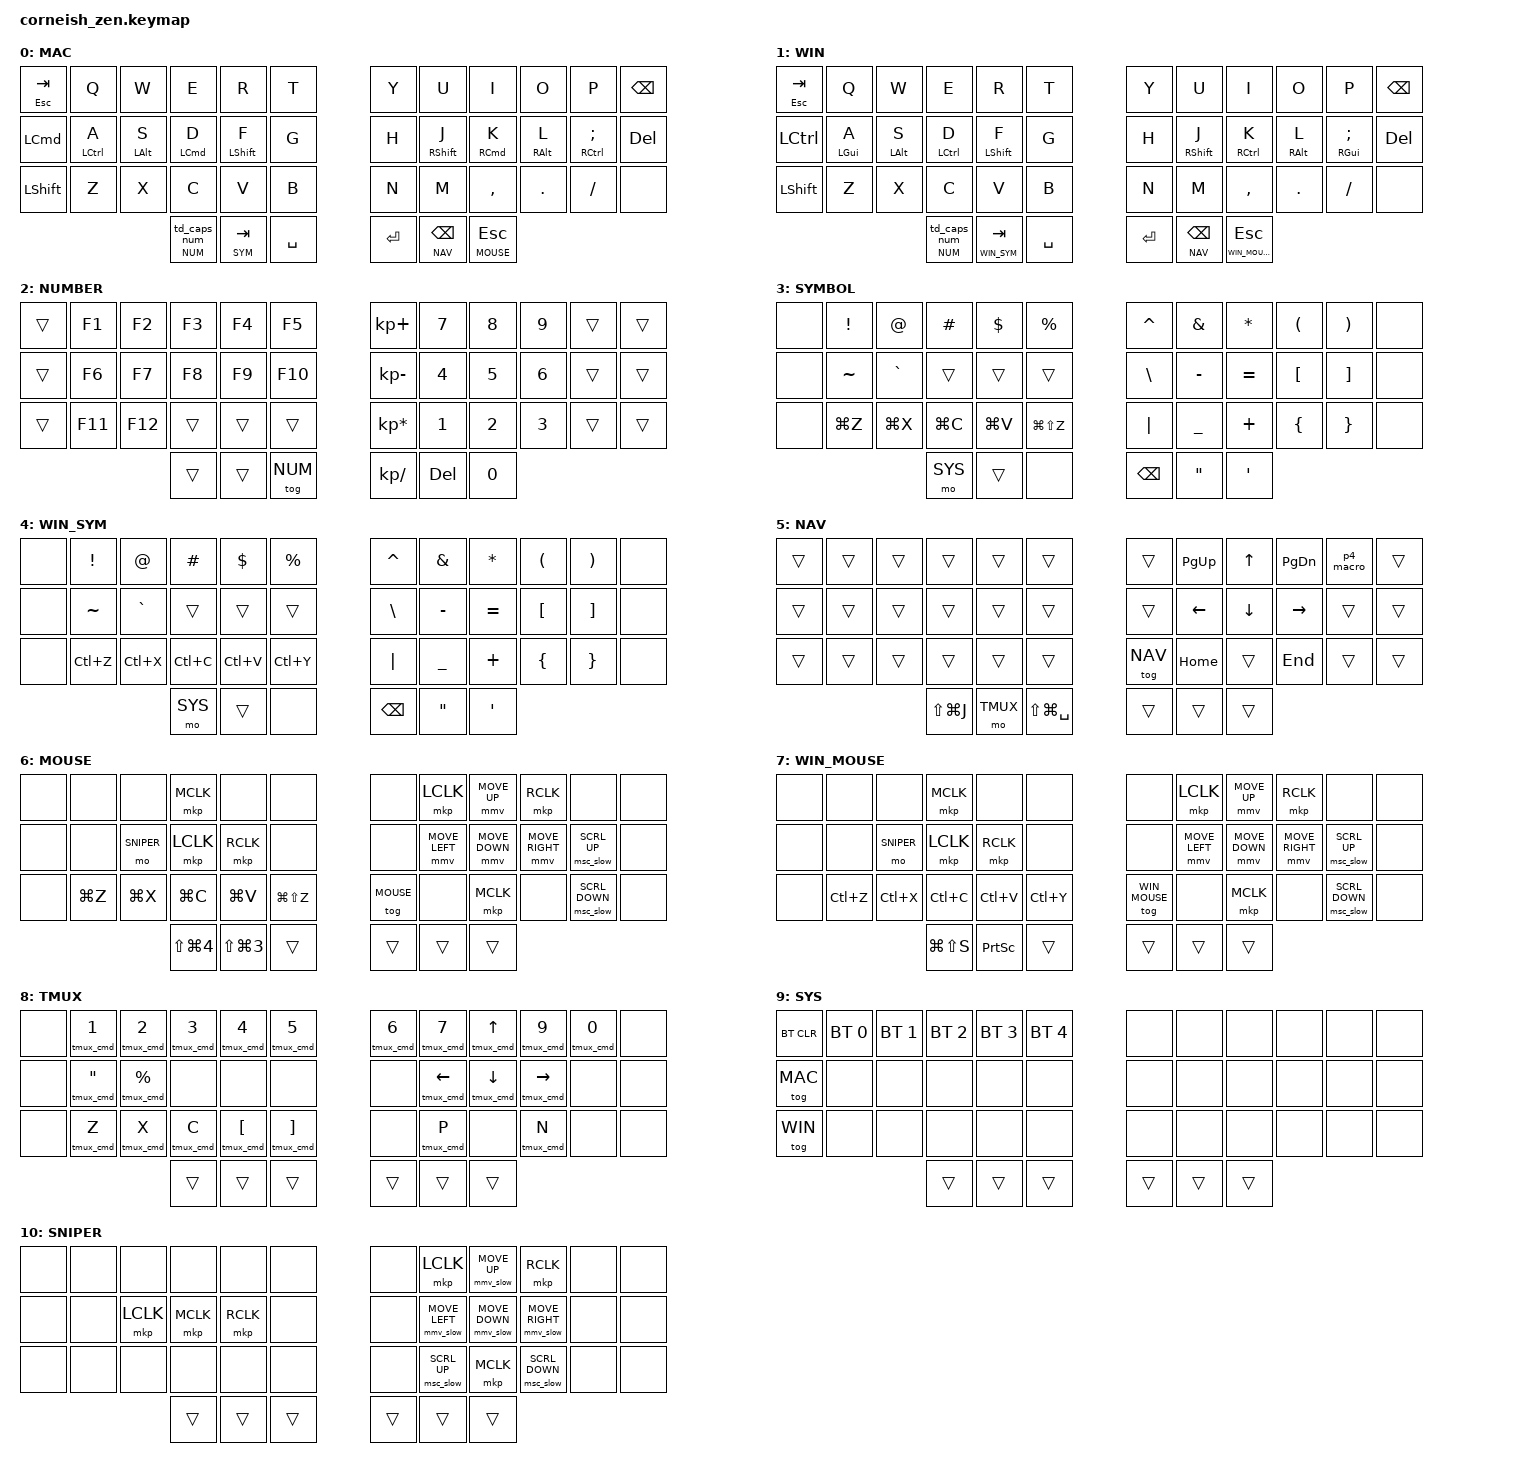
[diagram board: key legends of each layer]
#include <behaviors.dtsi>
#include <dt-bindings/zmk/keys.h>
#include <dt-bindings/zmk/bt.h>
#include <dt-bindings/zmk/pointing.h>

// 定義層級名稱（Layer Names）
#define MAC       0
#define WIN       1
#define NUM       2
#define SYM       3
#define WIN_SYM   4
#define NAV       5
#define MOUSE     6
#define WIN_MOUSE 7
#define TMUX      8
#define SYS       9
#define SNIPER   10
/* 頂部定義 Corne 鍵位索引別名 */
#define K_Q  1
#define K_W  2
#define K_E  3
#define K_R  4
#define K_T  5
#define K_Y  6
#define K_U  7
#define K_I  8
#define K_O  9
#define K_P 10

#define K_A 13
#define K_S 14
#define K_D 15
#define K_F 16
#define K_G 17
#define K_H 18
#define K_J 19
#define K_K 20
#define K_L 21
#define K_SEMI 22

#define K_Z 25
#define K_X 26
#define K_C 27
#define K_V 28
#define K_B 29
#define K_N 30
#define K_M 31
#define K_COMMA 32
#define K_DOT 33
#define K_SLASH 34

// 定義成對括號產生器模板
#define ZMK_PAIR_MACRO(name, left_key, right_key) \
    name: name { \
        compatible = "zmk,behavior-macro"; \
        #binding-cells = <0>; \
        wait-ms = <10>; \
        tap-ms = <10>; \
        bindings = <&kp left_key &kp right_key &kp LEFT>; \
    };

/* 基礎 2 鍵 Combo 模板 (預設只在 MAC 與 WIN 基礎層生效) */
#define ZMK_COMBO_2(NAME, BINDING, KEY1, KEY2) \
    combo_##NAME { \
        timeout-ms = <35>; \
        require-prior-idle-ms = <150>; \
        bindings = <BINDING>; \
        key-positions = <KEY1 KEY2>; \
        layers = <MAC WIN>; \
    };

/* 垂直捏合專用模板 (超短 timeout，單指觸發零誤觸) */
#define ZMK_VERTICAL_COMBO(NAME, BINDING, TOP_KEY, BOTTOM_KEY) \
    combo_vert_##NAME { \
        timeout-ms = <25>; \
        require-prior-idle-ms = <120>; \
        bindings = <BINDING>; \
        key-positions = <TOP_KEY BOTTOM_KEY>; \
        layers = <MAC WIN>; \
    };

/* 3 鍵爪形 Combo 模板 (系統級危險操作) */
#define ZMK_COMBO_3(NAME, BINDING, KEY1, KEY2, KEY3) \
    combo_##NAME { \
        timeout-ms = <50>; \
        bindings = <BINDING>; \
        key-positions = <KEY1 KEY2 KEY3>; \
        layers = <MAC WIN>; \
    };

/ {
    chosen {
        zmk,matrix_transform = &default_transform;
        // zmk,matrix_transform = &five_column_transform;
    };



    macros {
        tmux_cmd: tmux_cmd {
            compatible = "zmk,behavior-macro-one-param";
            #binding-cells = <1>;
            wait-ms = <10>;
            tap-ms = <10>;
            bindings
                = <&macro_press &kp LCTRL>
                , <&macro_tap &kp B>
                , <&macro_release &kp LCTRL>
                , <&macro_param_1to1>
                , <&macro_tap &kp MACRO_PLACEHOLDER>;
        };
        ZMK_PAIR_MACRO(pair_parens,   LPAR, RPAR)
        ZMK_PAIR_MACRO(pair_brackets, LBKT, RBKT)
        ZMK_PAIR_MACRO(pair_braces,   LBRC, RBRC)
        ZMK_PAIR_MACRO(pair_angles,   LT,   GT)
        ZMK_PAIR_MACRO(pair_dquotes,   DQT,  DQT)
        ZMK_PAIR_MACRO(pair_squotes,   SQT,  SQT)
        p4_macro: p4_macro {
            compatible = "zmk,behavior-macro";
            #binding-cells = <0>;
            wait-ms = <10>;
            tap-ms = <10>;
            bindings
                = <&kp P>
                , <&kp N4>;
        };
    };
    
    behaviors {
        hml: home_row_mod_left {
            compatible = "zmk,behavior-hold-tap";
            #binding-cells = <2>;
            flavor = "balanced";
            require-prior-idle-ms = <150>;
            tapping-term-ms = <280>;
            quick-tap-ms = <175>;
            bindings = <&kp>, <&kp>;
            hold-trigger-key-positions = <6 7 8 9 10 11 18 19 20 21 22 23 30 31 32 33 34 35 39 40 41>; // 右半部所有鍵位索引
            hold-trigger-on-release;
        };

        hmr: home_row_mod_right {
            compatible = "zmk,behavior-hold-tap";
            #binding-cells = <2>;
            flavor = "balanced";
            require-prior-idle-ms = <150>;
            tapping-term-ms = <280>;
            quick-tap-ms = <175>;
            bindings = <&kp>, <&kp>;
            hold-trigger-key-positions = <0 1 2 3 4 5 12 13 14 15 16 17 24 25 26 27 28 29 36 37 38>; // 左半部所有鍵位索引
            hold-trigger-on-release;
        };

        smart_caps: smart_caps {
            compatible = "zmk,behavior-caps-word";
            #binding-cells = <0>;
            continue-list = <UNDERSCORE MINUS BSPC DELETE>;
        };

        // 精準慢速移動游標（Sniper Move）
        mmv_slow: mmv_slow {
            compatible = "zmk,behavior-input-two-axis";
            #binding-cells = <1>;
            x-input-code = <INPUT_REL_X>;
            y-input-code = <INPUT_REL_Y>;
            time-to-max-speed-ms = <0>;
            acceleration-exponent = <0>;
        };

        // 精準慢速滾輪（Sniper Scroll）
        msc_slow: msc_slow {
            compatible = "zmk,behavior-input-two-axis";
            #binding-cells = <1>;
            x-input-code = <INPUT_REL_HWHEEL>;
            y-input-code = <INPUT_REL_WHEEL>;
            time-to-max-speed-ms = <0>;
            acceleration-exponent = <0>;
        };
        // num word
        // 1. 定義 Tap Dance：單擊輸出 CAPS，雙擊切換/鎖定 NUM 層
        td_caps_num: td_caps_num {
            compatible = "zmk,behavior-tap-dance";
            #binding-cells = <0>;
            tapping-term-ms = <200>;
            bindings = <&kp CAPS>, <&tog NUM>;
        };

        // 2. 定義複合 Hold-Tap：長按暫時切到 NUM 層，點擊交由 Tap Dance 處理
        lt_num_td: lt_num_td {
            compatible = "zmk,behavior-hold-tap";
            #binding-cells = <2>;
            flavor = "tap-preferred";
            tapping-term-ms = <200>;
            quick-tap-ms = <150>;
            bindings = <&mo>, <&td_caps_num>;
        };
    };

    combos {
        compatible = "zmk,combos";
        /* --- 系統控制 --- */
        
        ZMK_COMBO_2(caps_word,  &smart_caps,        K_Z, K_X)
        

        /* --- 垂直捏合：成對括號巨集 --- */
        ZMK_VERTICAL_COMBO(esc,        &kp ESC,            K_Q, K_A)
        ZMK_VERTICAL_COMBO(homerow,    &kp LS(LG(SPACE)),  K_F, K_V)
        
        ZMK_VERTICAL_COMBO(del,        &kp DEL,            K_T, K_G)
        ZMK_VERTICAL_COMBO(bspc,       &kp BSPC,           K_Y, K_H)
        ZMK_VERTICAL_COMBO(bspc2,       &kp BSPC,           K_SEMI, K_SLASH)

        ZMK_VERTICAL_COMBO(parens,   &pair_parens,   K_I, K_K)
        ZMK_VERTICAL_COMBO(brackets, &pair_brackets, K_O, K_L)
        ZMK_VERTICAL_COMBO(braces,   &pair_braces,   K_K, K_COMMA)
        ZMK_VERTICAL_COMBO(angles,   &pair_angles,   K_L, K_DOT)
        ZMK_VERTICAL_COMBO(squote,   &pair_squotes,   K_P, K_SEMI)
        

        ZMK_VERTICAL_COMBO(minus,   &kp MINUS,   K_U, K_J)
        /* --- 符號快捷 --- */
        ZMK_VERTICAL_COMBO(underscore,   &kp UNDER,   K_J, K_M)
        ZMK_VERTICAL_COMBO(dquote,   &pair_dquotes,   K_H, K_N)

        /* --- 3 鍵系統危險操作 --- */
        ZMK_COMBO_3(lock_screen, &kp LG(LC(Q)),     K_Q, K_W, K_E)
      
    };
};

/ {
    keymap {
        compatible = "zmk,keymap";

        // Layer 0: Mac 預設層
        default_layer {
            display-name = "MAC";
            bindings = <
    &mt ESC TAB     &kp Q        &kp W        &kp E        &kp R        &kp T     &kp Y   &kp U        &kp I        &kp O        &kp P           &kp BACKSPACE    
    &kp LCMD        &hml LCTRL A &hml LALT S  &hml LCMD D  &hml LSHFT F &kp G     &kp H   &hmr RSHFT J &hmr RCMD K  &hmr RALT L  &hmr RCTRL SEMI &kp DEL    
    &kp LSHFT       &kp Z        &kp X        &kp C        &kp V        &kp B     &kp N   &kp M        &kp COMMA    &kp DOT      &kp FSLH        &none  
                                        &lt_num_td NUM 0 &lt SYM TAB  &kp SPACE    &kp RET &lt NAV BACKSPACE         &lt MOUSE ESC   
            >;
        };

        // Layer 1: Windows 預設層
        win_layer {
            display-name = "WIN";
            bindings = <
    &mt ESC TAB   &kp Q        &kp W        &kp E        &kp R        &kp T     &kp Y   &kp U        &kp I        &kp O        &kp P           &kp BACKSPACE  
    &kp LCTRL     &hml LGUI A  &hml LALT S  &hml LCTRL D &hml LSHFT F &kp G     &kp H   &hmr RSHFT J &hmr RCTRL K &hmr RALT L  &hmr RGUI SEMI  &kp DEL    
    &kp LSHFT     &kp Z        &kp X        &kp C        &kp V        &kp B     &kp N   &kp M        &kp COMMA    &kp DOT      &kp FSLH        &none    
                                        &lt_num_td NUM 0 &lt WIN_SYM TAB &kp SPACE    &kp RET &lt NAV BACKSPACE      &lt WIN_MOUSE ESC   
            >;
        };

        // Layer 2: 數字層
        num_layer {
            display-name = "NUMBER";
            bindings = <
    &trans  &kp F1   &kp F2   &kp F3   &kp F4    &kp F5         &kp KP_PLUS         &kp N7  &kp N8  &kp N9  &trans   &trans     
    &trans  &kp F6   &kp F7   &kp F8   &kp F9    &kp F10        &kp KP_MINUS        &kp N4  &kp N5  &kp N6  &trans   &trans     
    &trans  &kp F11  &kp F12  &trans   &trans    &trans         &kp KP_MULTIPLY     &kp N1  &kp N2  &kp N3  &trans   &trans
                           &trans  &trans  &tog NUM            &kp KP_DIVIDE       &kp DEL &kp N0  
            >;
        };

        // Layer 3: Mac 符號與快捷鍵層
        symbol_layer {
            display-name = "SYMBOL";
            bindings = <
    &none  &kp EXCL  &kp AT    &kp HASH  &kp DLLR  &kp PRCNT       &kp CARET  &kp AMPS   &kp STAR        &kp LPAR  &kp RPAR  &none
    &none  &kp TILDE &kp GRAVE &trans    &trans    &trans          &kp BSLH   &kp MINUS  &kp EQUAL       &kp LBKT  &kp RBKT  &none
    &none  &kp LG(Z) &kp LG(X) &kp LG(C) &kp LG(V) &kp LG(LS(Z))   &kp PIPE   &kp UNDER  &kp PLUS        &kp LBRC  &kp RBRC  &none
                               &mo SYS     &trans    &none       &kp BSPC   &kp DQT    &kp SQT
            >;
        };

        // Layer 4: Windows 符號與快捷鍵層
        win_symbol_layer {
            display-name = "WIN_SYM";
            bindings = <
    &none  &kp EXCL  &kp AT    &kp HASH  &kp DLLR  &kp PRCNT   &kp CARET  &kp AMPS   &kp STAR        &kp LPAR  &kp RPAR  &none
    &none  &kp TILDE &kp GRAVE &trans    &trans    &trans      &kp BSLH   &kp MINUS  &kp EQUAL       &kp LBKT  &kp RBKT  &none
    &none  &kp LC(Z) &kp LC(X) &kp LC(C) &kp LC(V) &kp LC(Y)   &kp PIPE   &kp UNDER  &kp PLUS        &kp LBRC  &kp RBRC  &none
                               &mo SYS     &trans    &none       &kp BSPC   &kp DQT    &kp SQT
            >;
        };

        // Layer 5: 導航層
        nav_layer {
            display-name = "NAV";
            bindings = <
    &trans  &trans             &trans    &trans  &trans  &trans  &trans     &kp PG_UP &kp UP    &kp PG_DN  &p4_macro  &trans    
    &trans  &trans             &trans    &trans  &trans  &trans  &trans     &kp LEFT  &kp DOWN  &kp RIGHT  &trans     &trans    
    &trans  &trans             &trans    &trans  &trans  &trans  &tog NAV   &kp HOME  &trans    &kp END    &trans     &trans    
            &kp LS(LG(J))  &mo TMUX  &kp LS(LG(SPACE))  &trans  &trans  &trans  
            >;
        };

        // Layer 6: Mac 滑鼠與截圖層（已移除藍牙控制）
        mouse_layer {
            display-name = "MOUSE";
            bindings = <
    &none   &none         &none         &mkp MCLK     &none         &none           &none        &mkp LCLK          &mmv MOVE_UP    &mkp RCLK            &none               &none    
    &none   &none         &mo SNIPER    &mkp LCLK     &mkp RCLK     &none           &none        &mmv MOVE_LEFT     &mmv MOVE_DOWN  &mmv MOVE_RIGHT      &msc_slow SCRL_UP   &none    
    &none   &kp LG(Z)     &kp LG(X)     &kp LG(C)     &kp LG(V)     &kp LG(LS(Z))   &tog MOUSE   &none              &mkp MCLK       &none                &msc_slow SCRL_DOWN &none    
                                        &kp LS(LG(N4)) &kp LS(LG(N3)) &trans        &trans  &trans          &trans  
            >;
        };

        // Layer 7: Windows 滑鼠與截圖層（已移除藍牙控制）
        win_mouse_layer {
            display-name = "WIN_MOUSE";
            bindings = <
    &none   &none         &none         &mkp MCLK     &none         &none           &none            &mkp LCLK          &mmv MOVE_UP    &mkp RCLK            &none               &none    
    &none   &none         &mo SNIPER    &mkp LCLK     &mkp RCLK     &none           &none            &mmv MOVE_LEFT     &mmv MOVE_DOWN  &mmv MOVE_RIGHT      &msc_slow SCRL_UP   &none    
    &none   &kp LC(Z)     &kp LC(X)     &kp LC(C)     &kp LC(V)     &kp LC(Y)       &tog WIN_MOUSE   &none              &mkp MCLK       &none                &msc_slow SCRL_DOWN  &none    
                                        &kp LG(LS(S)) &kp PSCRN     &trans          &trans  &trans          &trans  
            >;
        };

        // Layer 8: Tmux 共用層
        tmux_layer {
            display-name = "TMUX";
            bindings = <
    &none  &tmux_cmd N1   &tmux_cmd N2   &tmux_cmd N3  &tmux_cmd N4   &tmux_cmd N5   &tmux_cmd N6  &tmux_cmd N7    &tmux_cmd UP    &tmux_cmd N9     &tmux_cmd N0   &none
    &none  &tmux_cmd DQT  &tmux_cmd PRCNT&none         &none          &none          &none         &tmux_cmd LEFT  &tmux_cmd DOWN  &tmux_cmd RIGHT  &none          &none
    &none  &tmux_cmd Z    &tmux_cmd X    &tmux_cmd C   &tmux_cmd LBKT &tmux_cmd RBKT &none         &tmux_cmd P     &none           &tmux_cmd N      &none          &none
                                         &trans        &trans         &trans         &trans        &trans          &trans
            >;
        };

        // Layer 9: 獨立系統/硬體管理層
        sys_layer {
            display-name = "SYS";
            bindings = <
    &bt BT_CLR   &bt BT_SEL 0  &bt BT_SEL 1  &bt BT_SEL 2  &bt BT_SEL 3  &bt BT_SEL 4    &none  &none  &none  &none  &none  &none
    &tog MAC   &none         &none         &none         &none         &none           &none  &none  &none  &none  &none  &none
    &tog WIN  &none         &none         &none         &none         &none           &none  &none  &none  &none  &none  &none
                                             &trans        &trans        &trans          &trans &trans &trans
            >;
        };
        // Layer 10: slow mouse
        sniper_layer {
            display-name = "SNIPER";
            bindings = <
    &none   &none  &none      &none      &none     &none     &none   &mkp LCLK            &mmv_slow MOVE_UP    &mkp RCLK             &none      &none    
    &none   &none  &mkp LCLK  &mkp MCLK  &mkp RCLK &none     &none   &mmv_slow MOVE_LEFT  &mmv_slow MOVE_DOWN  &mmv_slow MOVE_RIGHT  &none      &none    
    &none   &none  &none      &none      &none     &none     &none   &msc_slow SCRL_UP    &mkp MCLK            &msc_slow SCRL_DOWN   &none      &none    
                              &trans     &trans    &trans    &trans  &trans               &trans  
            >;
        };
    };
};
